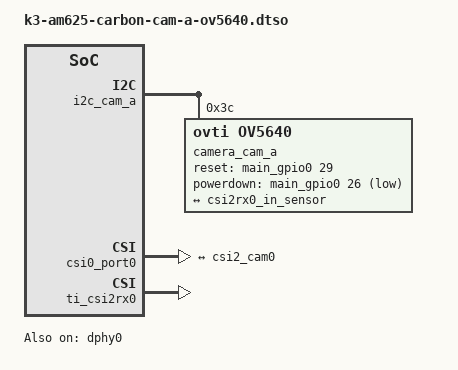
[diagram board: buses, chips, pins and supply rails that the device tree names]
 // SPDX-License-Identifier: GPL-2.0
/*
 * Digilent Pcam 5C 5MP OV5640 camera module
 *
 * Copyright (C) 2024 Ezurio LLC
 */

/dts-v1/;
/plugin/;

#include <dt-bindings/gpio/gpio.h>
#include "k3-pinctrl.h"

&{/} {
	/* On Camera module oscillator */
	clk_cam_a_int: clk-cam-a-int {
		compatible = "fixed-clock";
		#clock-cells = <0>;
		clock-frequency = <12000000>;
	};
};

&i2c_cam_a {
	#address-cells = <1>;
	#size-cells = <0>;

	camera_cam_a: camera-cam-a@3c {
		compatible = "ovti,ov5640";
		reg = <0x3c>;

		clocks = <&clk_cam_a_int>; /* On Camera module */
		clock-names = "xclk";

		pinctrl-names = "default";
		pinctrl-0 = <&main_cam_a_default>;
		reset-gpios = <&main_gpio0 29 GPIO_ACTIVE_HIGH>;
		powerdown-gpios = <&main_gpio0 26 GPIO_ACTIVE_LOW>; /* CAM_A_PWR */

		port {
			csi2_cam0: endpoint {
				remote-endpoint = <&csi2rx0_in_sensor>;
				clock-lanes = <0>;
				data-lanes = <1 2>;
			};
		};
	};
};

&csi0_port0 {
	status = "okay";

	csi2rx0_in_sensor: endpoint {
		remote-endpoint = <&csi2_cam0>;
		bus-type = <4>; /* CSI2 DPHY. */
		clock-lanes = <0>;
		data-lanes = <1 2>;
	};
};

&ti_csi2rx0 {
	status = "okay";
};

&dphy0 {
	status = "okay";
};
